AUTOSAR XML (schema 4-3-0)
package /CAN_System
  sender receiver interface Uint16
    data Uint16: type=uint16
package /CAN_System/Pkg_Ecu/TestComponent
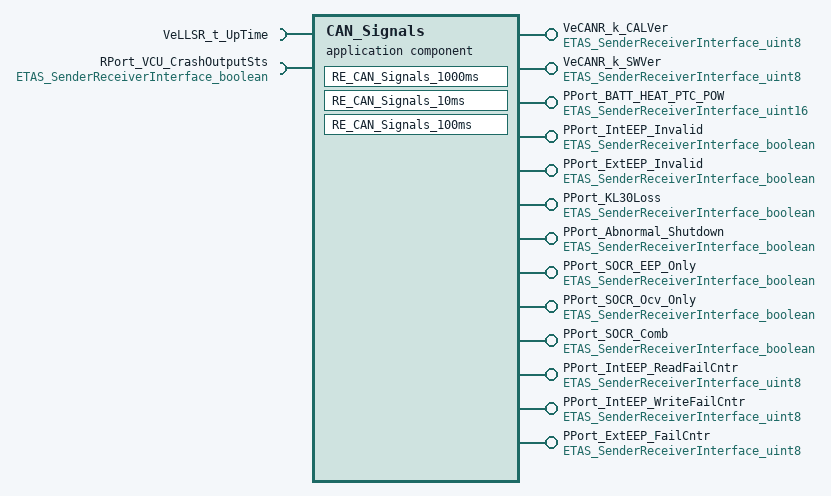
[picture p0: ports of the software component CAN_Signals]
  application sw component type CAN_Signals
    require port VeLLSR_t_UpTime: required-interface=VeLLSR_t_UpTime
    provide port VeCANR_k_CALVer: provided-interface=ETAS_SenderReceiverInterface_uint8
    provide port VeCANR_k_SWVer: provided-interface=ETAS_SenderReceiverInterface_uint8
    provide port PPort_BATT_HEAT_PTC_POW: provided-interface=ETAS_SenderReceiverInterface_uint16
    require port RPort_VCU_CrashOutputSts: nonqueued-receiver-com-spec{data-element=boolean, enable-update=true}, required-interface=ETAS_SenderReceiverInterface_boolean
    10 x provide port:
      PPort_IntEEP_Invalid: provided-interface=ETAS_SenderReceiverInterface_boolean
      PPort_ExtEEP_Invalid: provided-interface=ETAS_SenderReceiverInterface_boolean
      PPort_KL30Loss: provided-interface=ETAS_SenderReceiverInterface_boolean
      PPort_Abnormal_Shutdown: provided-interface=ETAS_SenderReceiverInterface_boolean
      PPort_SOCR_EEP_Only: provided-interface=ETAS_SenderReceiverInterface_boolean
      PPort_SOCR_Ocv_Only: provided-interface=ETAS_SenderReceiverInterface_boolean
      PPort_SOCR_Comb: provided-interface=ETAS_SenderReceiverInterface_boolean
      PPort_IntEEP_ReadFailCntr: provided-interface=ETAS_SenderReceiverInterface_uint8
      PPort_IntEEP_WriteFailCntr: provided-interface=ETAS_SenderReceiverInterface_uint8
      PPort_ExtEEP_FailCntr: provided-interface=ETAS_SenderReceiverInterface_uint8
    behavior IB_Test: data-type-mapping=[CSCR_CodeDataTypeMappingsSet, VSDR_CodeDataTypeMappingsSet, THMR_CodeDataTypeMappingsSet, ISLR_CodeDataTypeMappingsSet, HVIR_CodeDataTypeMappingsSet, CPLR_CodeDataTypeMappingsSet, CFLR_CodeDataTypeMappingsSet, DHSR_CodeDataTypeMappingsSet, SOCR_CodeDataTypeMappingsSet, SOPR_CodeDataTypeMappingsSet, CHMR_CodeDataTypeMappingsSet]
      4 x timing event:
        TE_CAN_1000ms: start-on-event=RE_CAN_Signals_1000ms, period=1.0
        TE_CAN_10ms: start-on-event=RE_CAN_Signals_10ms, period=0.01
        TE_CAN_500ms: period=0.5
        TE_CAN_100ms: start-on-event=RE_CAN_Signals_100ms, period=0.1
      per instance memory NvRamMirror: implementation-data-type=uint32, type=NvRamMirrorType, type-definition=uint32
      runnable RE_CAN_Signals_1000ms: symbol=RE_CAN_Signals_1000msfunc
        data-receive-point-by-values:
          access DRPV_VeLLSR_t_UpTime_0: accessed-variable=VeLLSR_t_UpTime.VeLLSR_t_UpTime
        data-send-points:
          access DSP_uint8_0: accessed-variable=VeCANR_k_CALVer.uint8
          access DSP_uint8_1: accessed-variable=VeCANR_k_SWVer.uint8
          access DSP_uint16_0: accessed-variable=PPort_BATT_HEAT_PTC_POW.uint16
        parameter access PAP_Ke_WinterTestingDbcFeatures: accessed-parameter=Ke_WinterTestingDbcFatures
      runnable RE_CAN_Signals_10ms
        data-receive-point-by-values:
          access DRPV_boolean_0: accessed-variable=RPort_VCU_CrashOutputSts.boolean
        data-write-access:
          10 x access:
            DWA_boolean_0: accessed-variable=PPort_SOCR_Comb.boolean
            DWA_boolean_1: accessed-variable=PPort_SOCR_EEP_Only.boolean
            DWA_boolean_2: accessed-variable=PPort_Abnormal_Shutdown.boolean
            DWA_boolean_3: accessed-variable=PPort_KL30Loss.boolean
            DWA_uint8_0: accessed-variable=PPort_IntEEP_ReadFailCntr.uint8
            DWA_uint8_4: accessed-variable=PPort_IntEEP_WriteFailCntr.uint8
            DWA_boolean_4: accessed-variable=PPort_IntEEP_Invalid.boolean
            DWA_boolean_5: accessed-variable=PPort_SOCR_Ocv_Only.boolean
            DWA_uint8_5: accessed-variable=PPort_ExtEEP_FailCntr.uint8
            DWA_boolean_6: accessed-variable=PPort_ExtEEP_Invalid.boolean
      runnable RE_CAN_Signals_100ms
      shared-parameters:
        parameter data prototype Ke_WinterTestingDbcFatures: sw-calibration-access=READ-WRITE, implementation-data-type=Boolean, type=Boolean, init-value=0
  sender receiver interface ETAS_SenderReceiverInterface_boolean
    data boolean: type=boolean
  sender receiver interface SenderReceiverInterface_0
    data DataElements_0: type=boolean
  sender receiver interface SenderReceiverInterface_1
    data DataElements_0: type=boolean
  app type ApplicationPrimitiveDataType_1: category=VALUE
  app type ApplicationPrimitiveDataType_2: category=VALUE
package /CAN_System/Pkg_Ecu/Interfaces
  5 x sender receiver interface:
    ETAS_SenderReceiverInterface_uint16
      data uint16: type=uint16
    ETAS_SenderReceiverInterface_uint32
      data uint32: type=uint32
    ETAS_SenderReceiverInterface_uint8
      data uint8: type=uint8
    ETAS_SenderReceiverInterface_sint16
      data sint16: type=sint16
    ETAS_SenderReceiverInterface_Float
      data Float: type=Float
package /CAN_System/ARPackage
  sender receiver interface VeCANR_CellVoltageValue_Out
    data DataElements_VariableDataPrototype_0: sw-calibration-access=READ-ONLY, implementation-data-type=UInt8, type=uint16
